# M030GAE register map
File version: 1.0
Registers are 32-bit, read-write, reset 0x0 unless marked. A register's access mark holds for its fields unless they carry their own. Offsets are from the block's base; [hi:lo] are bit positions.

## MANCH — Manchester Register Map
Base 0x400BC000
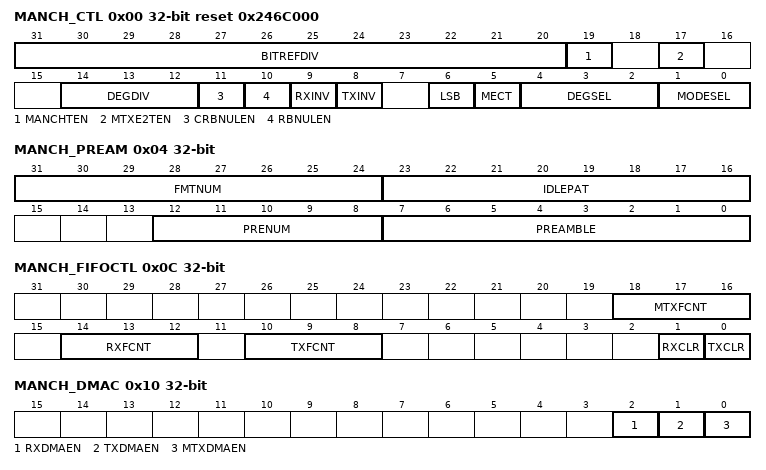
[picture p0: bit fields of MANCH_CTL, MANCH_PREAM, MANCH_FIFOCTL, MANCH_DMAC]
0x00 MANCH_CTL reset 0x246C000 — Manchester Function Control Register
  [31:20] BITREFDIV — Manchester Bit Reference Clock Divider. The bits field indicates the reference clock frequency for Manchester bit sample. For example, if the PCLK0 is 72 MHz, the BITREFDIV can be set as 0x23 (BITREFDIV+1). It will generate 2 MHz reference clock frequency and the Manchester transmitting or receiving data is sampled with the reference divided clock. Note 1: The BITREFDIV minimum value is 0x03. Note 2: It is suggested that minimize the BITREFDIV value to make the TBITNUM or RTIBNUM value be greater than 0x64.
  [19] MANCHTEN — Manchester Transmit Enable
    0=Manchester Transmit Disabled; 1=Manchester Transmit Enabled. It will be cleared to 0 after the data frame transmission done
  [17] MTXE2TEN — Manchester Coded Edge Output Enable Bit
    0=Manchester coded edge signal outputs to Timer Controller Disabled; 1=Manchester coded edge signal outputs to Timer Controller Enabled
  [14:12] DEGDIV — Manchester Deglitch Clock Divider. The bits field indicates the deglitched clock frequency. The detail is described in Deglitch Selection section.
  [11] CRBNULEN — Current Received Bit Clock Number Auto Upload Enable Bit
    0=CRBITNUM is not updated in each received byte during message receiving period; 1=CRBITNUM is updated in each received byte during message receiving period
  [10] RBNULEN — Received Bit Clock Number Auto Upload Enable Bit
    0=RBITNUM is not updated by CRBITNUM at each data frame beginning; 1=RBITNUM is updated by CRBITNUM at each data frame beginning
  [9] RXINV — Receive Signal Invert
    0=The received data is not inverted; 1=The received data is inverted
  [8] TXINV — Transmit Signal Invert
    0=The transmitting data is not inverted; 1=The transmitting data is inverted
  [6] LSB — Manchester Code LSB First. Note: This bit should be configured before MODSEL
    0=Manchester code is MSB first; 1=Manchester code is LSB first
  [5] MECT — Manchester Encoding Type. Level 0: the signal is half cycle high and transfer to half cycle low. Level 1: the signal is half cycle low and transfer to half cycle high. Note: Please refer to Figure 6.165.
    0=G.E Thomas format; 1=IEEE 802.3 format
  [4:2] DEGSEL — Received Deglitch Selection. The bits field is used to define how much width of glitch would be filtered.
    0=disable to the Manchester deglitch selection; 1=Filter the glitches that the width is 0.25us or less; 2=Filter the glitches that the width is 0.50us or less; 3=Filter the glitches that the width is 0.75us or less; 4=Filter the glitches that the width is 1.00us or less; 5=Filter the glitches that the width is 1.25us or less
  [1:0] MODESEL — Manchester Mode Selection. Note: All the change of function setting shall be during Manchester Controller disabled.
    0=Manchester function is disabled; 1=Mode 1 modulation signal format is selected; 2=Mode 2 modulation signal format is selected; 3=The other modulation signal format is selected. (The register of MANCH_PREAM shall be set according to its frame information.)
0x04 MANCH_PREAM — Manchester Preamble Register
  [31:24] FMTNUM — Modulation Format Transmit Number. The bits field defines the number of transmitted byte number in current selected mode. If MODESEL is 0x1, the FMTNUM will be forced as 0x1E. If MODESEL is 0x2, the FMTNUM will be forced as 0x40. If MODESEL is 0x3, the modulation transmit number will be FMTNUM. Note 1: If FMTNUM is 0x00, which indicates the transmit number is 256 Bytes. Note 2: The value of FMTNUM must be greater than PRENUM. Note 3: The minimum value of FMTNUM must be greater than 1.
  [23:16] IDLEPAT — Idle Pattern. The bits field indicates the bus idle pattern. If it is 0x00, it indicates that the bus idle default is low. If it is 0xFF, it indicates that the bus idle default is high. Except the bus idle state is LOW, the bits field must be set before the Controller is Enabled.
  [12:8] PRENUM — Preamble Number. The bits field defines the number of preamble in the modulation signal format. 00000: means there are 32 preamble patterns. 00001: means there is 1 preamble pattern. 00010: means there are 2 preamble patterns. 00011: means there are 3 preamble patterns. and so on. If MODESEL is 2'b01, the PRENUM will be set as 0x5. If MODESEL is 2'b10, the PRENUM will be set as 0x4.
  [7:0] PREAMBLE — Preamble Format. The bits field defines the preamble pattern in the modulation signal format. If MODESEL is 2'b10, the PREAMBLE will be set as 0x7E.
0x0C MANCH_FIFOCTL — Manchester FIFO Control Register
  [18:16] MTXFCNT ro — Manchester Transmit Encoded FIFO Count (Read Only). The bits field indicates the current counter number of transmitted encoded FIFO for encoded data.
  [14:12] RXFCNT ro — Received FIFO Count (Read Only). The bits field indicates the current counter number of received FIFO for decoded data.
  [10:8] TXFCNT ro — Transmitted FIFO Count (Read Only). The bits field indicates the current counter number of transmitted FIFO for transmitting data.
  [1] RXCLR — Received FIFO Clear. Note: The received control includes the FIFO and receive state machine. For example, if there is noise in the bus, the Manchester Controller will report BITERR flag when it detects the bit width greater than the setting. If the number of bit error event is greater than the software threshold, then set RXCLR to reset the receive state machine. The Manchester Controller will re-detect the IDLEPAT again.
    0=Received control is not cleared; 1=Received control is cleared
  [0] TXCLR — Transmit FIFO Clear
    0=Both of Transmit FIFO and Manchester Transmit encoded FIFO are not cleared; 1=Both of Transmit FIFO and Manchester Transmit encoded FIFO are cleared
0x10 MANCH_DMAC — Manchester DMA Control Register
  [2] RXDMAEN — Received DMA Enable Bit
    0=Received DMA Disabled; 1=Received DMA Enabled
  [1] TXDMAEN — Transmit DMA Enable Bit
    0=Transmit DMA Disabled; 1=Transmit DMA Enabled
  [0] MTXDMAEN — Manchester Code Transmit DMA Enable Bit
    0=Manchester Code Transmit DMA Disabled; 1=Manchester Code Transmit DMA Enabled
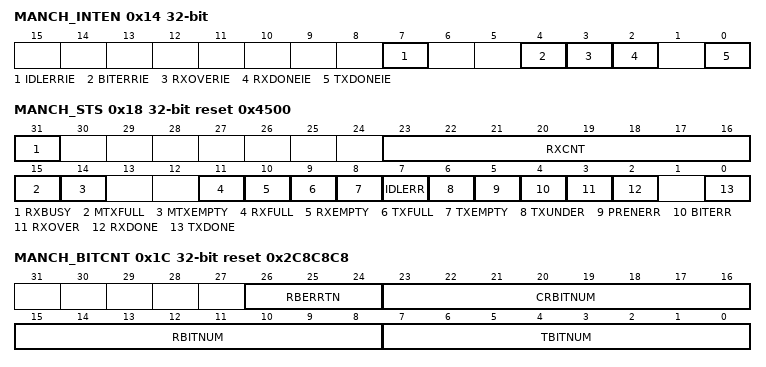
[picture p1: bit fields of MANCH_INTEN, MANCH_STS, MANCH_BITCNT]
0x14 MANCH_INTEN — Manchester Interrupt Enable Register
  [7] IDLERRIE — IDLE Pattern Error Interrupt Enable Bit
    0=The Idle pattern error detected interrupt Disabled; 1=The Idle pattern error detected interrupt Enabled
  [4] BITERRIE — Bit Detect Error Interrupt Enable Bit
    0=The Manchester bit error detected interrupt Disabled; 1=The Manchester bit error detected interrupt Enabled
  [3] RXOVERIE — Receive FIFO Overflow Interrupt Enable Bit
    0=Receive FIFO overflow interrupt Disabled; 1=Receive FIFO overflow interrupt Enabled
  [2] RXDONEIE — Receive Frame Done Interrupt Enable Bit
    0=Receive frame done interrupt Disabled; 1=Receive frame done interrupt Enabled
  [0] TXDONEIE — Transmit Done Interrupt Enable Bit
    0=Transmit frame done interrupt Disabled; 1=Transmit frame done interrupt Enabled
0x18 MANCH_STS reset 0x4500 — Manchester Status Register
  [31] RXBUSY — Receive Busy Flag
    0=The received bus is not busy; 1=The received bus is busy
  [23:16] RXCNT — Receive Frame Data Current Count
  [15] MTXFULL — Manchester Transmit Encoded FIFO Full
    0=The Manchester transmit encoded FIFO is not full; 1=The Manchester transmit encoded FIFO is full
  [14] MTXEMPTY — Manchester Transmit Encoded FIFO Empty
    0=The Manchester transmit encoded FIFO is not empty; 1=The Manchester transmit encoded FIFO is empty
  [11] RXFULL — Received FIFO Full
    0=The received FIFO is not full; 1=The received FIFO is full
  [10] RXEMPTY — Received FIFO Empty
    0=The received FIFO is not empty; 1=The received FIFO is empty
  [9] TXFULL — Transmit FIFO Full
    0=The transmit FIFO is not full; 1=The transmit FIFO is full
  [8] TXEMPTY — Transmit FIFO Empty
    0=The transmit FIFO is not empty; 1=The transmit FIFO is empty
  [7] IDLERR — IDLE Error. Note: This bit can be cleared by writing 1 to it.
    0=The receive Idle pattern error is not detected; 1=The receive Idle pattern error is detected
  [6] TXUNDER — Transmit FIFO Underrun. Note: This bit can be cleared by writing 1 to it.
    0=The transmit FIFO is not underrun; 1=The transmit FIFO is underrun
  [5] PRENERR — Preamble Number Error. Note: This bit can be cleared by writing 1 to it.
    0=The receive preamble number error is not detected; 1=The receive preamble number error is detected
  [4] BITERR — Manchester Bit Error. Note: This bit can be cleared by writing 1 to it.
    0=The Manchester bit error is not detected; 1=The Manchester bit error is detected. If the counter between two receive edge is greater than (RBITNUM + bit error tolerance) or less than (RBITNUM - bit error tolerance)
  [3] RXOVER — Receive FIFO Overflow. Note: This bit can be cleared by writing 1 to it.
    0=The receive FIFO is not overflow; 1=The receive FIFO is overflow
  [2] RXDONE — Receive Frame Done. Note: This bit can be cleared by writing 1 to it.
    0=Receive frame is not done; 1=Receive frame is done
  [0] TXDONE — Transmit Frame Done. Note: When the MANCHTEN is set, this bit will keep 0 until the data frame transmission is done.
    0=Transmit frame is not done; 1=Transmit frame is done
0x1C MANCH_BITCNT reset 0x2C8C8C8 — Manchester Bit Count Register
  [26:24] RBERRTN — Manchester Receive Bit Error Tolerance Number. The bits field indicates the tolerance range of RBITNUM for received bit to detect the bit error event.
    0=1/4 RBITNUM as the bit error tolerance; 1=1/8 RBITNUM as the bit error tolerance; 2=1/16 RBITNUM as the bit error tolerance; 3=1/32 RBITNUM as the bit error tolerance; 4=1/64 RBITNUM as the bit error tolerance; 5=1/128 RBITNUM as the bit error tolerance
  [23:16] CRBITNUM ro — Manchester Current Receive Reference Frequency Number per Bit (Read Only). The bits field indicates the current number of reference frequency (Bit_Ref_Clock) for each received bit.
  [15:8] RBITNUM — Manchester Receive Reference Clock Number per Bit. The bits field indicates the number of reference clock (Bit_Ref_Clock) for received bit. If there is not BITERR event, user can refer to the CRBITNUM to revise the RBITNUM. Note 1: The value of this bits field cannot be 0x00 and the tolerance value must be not 3% than the received input bit rate. Otherwise, it cannot receive the correct input data on time. Note 2: The bits can be updated at the start of next data frame if the RBNULEN is set to 1. Note 3: It is suggested that the RBITNUM value is not less than 0x64.
  [7:0] TBITNUM — Manchester Transmit Reference Clock Number per Bit. The bits field indicates the number of reference clock (Bit_Ref_Clock) for transmit bit. Note 1: The value of this bits field cannot be 0x00. Note 2: It is suggested the TBITNUM value is not less than 0x64.
0x20 MANCH_TXDAT — Manchester Transmit Data Register
  [7:0] TXDAT — Manchester Transmit Data. The bits field indicates the transmit data.
0x24 MANCH_RXDAT ro — Manchester Receive Data Register
  [7:0] RXDAT — Manchester Receive Data. The bits field indicates the received data.
0x28 MANCH_MTXDAT ro — Manchester Transmit Encoded Data Register
  [15:0] MTXDAT — Manchester Encoded Data. The bits field indicates the current Manchester encoded data in FIFO.
